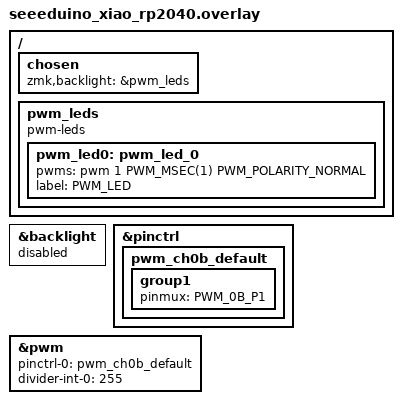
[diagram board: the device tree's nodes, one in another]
#include <dt-bindings/pinctrl/rpi-pico-rp2040-pinctrl.h>
#include <dt-bindings/pwm/pwm.h>

&backlight { status = "disabled"; };

&pinctrl {
	pwm_ch0b_default: pwm_ch0b_default {
		group1 {
			pinmux = <PWM_0B_P1>;
		};
	};
};

/ {

	chosen {
		zmk,backlight = &pwm_leds;
	};

	pwm_leds: pwm_leds {
		compatible = "pwm-leds";
		pwm_led0: pwm_led_0 {
			status = "okay";
			pwms = <&pwm 1 PWM_MSEC(1) PWM_POLARITY_NORMAL>;
			label = "PWM_LED";
		};
	};
};

&pwm {
	status = "okay";
	pinctrl-0 = <&pwm_ch0b_default>;
	pinctrl-names = "default";
	divider-int-0 = <255>;
};
